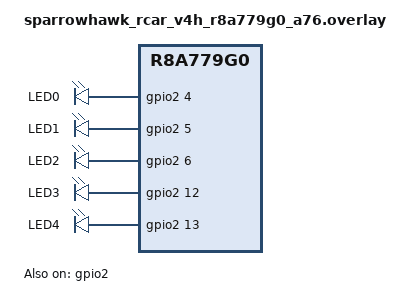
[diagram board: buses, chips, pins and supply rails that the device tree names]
/*
 * Copyright (C) 2025 TOKITA Hiroshi
 *
 * SPDX-License-Identifier: Apache-2.0
 */

#include <mem.h>
#include <zephyr/dt-bindings/gpio/gpio.h>

/ {
	aliases {
		led0 = &led0;
		led1 = &led1;
		led2 = &led2;
		led3 = &led3;
		led4 = &led4;
	};

	leds {
		compatible = "gpio-leds";

		led0: led0 {
			gpios = <&gpio2 4 GPIO_ACTIVE_HIGH>;
			label = "LED0";
		};

		led1: led1 {
			gpios = <&gpio2 5 GPIO_ACTIVE_HIGH>;
			label = "LED1";
		};

		led2: led2 {
			gpios = <&gpio2 6 GPIO_ACTIVE_HIGH>;
			label = "LED2";
		};

		led3: led3 {
			gpios = <&gpio2 12 GPIO_ACTIVE_HIGH>;
			label = "LED3";
		};

		led4: led4 {
			gpios = <&gpio2 13 GPIO_ACTIVE_HIGH>;
			label = "LED4";
		};

	};

	gpio2: gpio@e6058180 {
		compatible = "renesas,rcar-gpio";
		reg = <0x0 0xe6058180 0x0 0x54>;
		#gpio-cells = <2>;
		gpio-controller;
		interrupts = <GIC_SPI 627 IRQ_TYPE_LEVEL IRQ_DEFAULT_PRIORITY>;
		clocks = <&cpg CPG_MOD 916>;
		status = "okay";
	};
};
